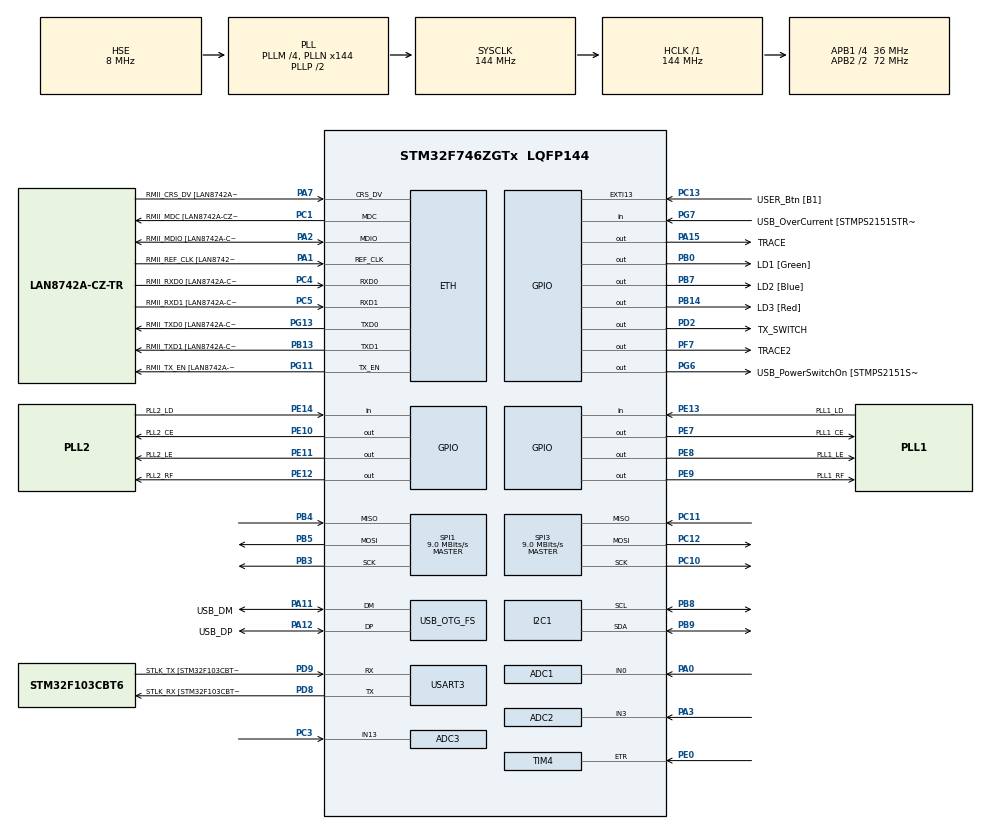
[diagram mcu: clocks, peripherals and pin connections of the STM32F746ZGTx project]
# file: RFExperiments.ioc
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ADC1.Channel-9\#ChannelRegularConversion=ADC_CHANNEL_0
ADC1.ClockPrescaler=ADC_CLOCK_SYNC_PCLK_DIV2
ADC1.ContinuousConvMode=DISABLE
ADC1.DMAAccessMode=ADC_DMAACCESSMODE_1
ADC1.DMAContinuousRequests=ENABLE
ADC1.ExternalTrigConv=ADC_EXTERNALTRIGCONV_T4_TRGO
ADC1.Mode=ADC_TRIPLEMODE_REGSIMULT
ADC1.NbrOfConversionFlag=1
ADC1.Rank-9\#ChannelRegularConversion=1
ADC1.SamplingTime-9\#ChannelRegularConversion=ADC_SAMPLETIME_3CYCLES
ADC1.master=1
ADC2.Channel-0\#ChannelRegularConversion=ADC_CHANNEL_3
ADC2.ContinuousConvMode=DISABLE
ADC2.DMAAccessMode=ADC_DMAACCESSMODE_1
ADC2.DMAContinuousRequests=DISABLE
ADC2.Mode=ADC_TRIPLEMODE_REGSIMULT
ADC2.NbrOfConversionFlag=1
ADC2.Rank-0\#ChannelRegularConversion=1
ADC2.SamplingTime-0\#ChannelRegularConversion=ADC_SAMPLETIME_3CYCLES
ADC3.Channel-10\#ChannelRegularConversion=ADC_CHANNEL_13
ADC3.ContinuousConvMode=DISABLE
ADC3.DMAAccessMode=ADC_DMAACCESSMODE_1
ADC3.DMAContinuousRequests=DISABLE
ADC3.Mode=ADC_TRIPLEMODE_REGSIMULT
ADC3.NbrOfConversionFlag=1
ADC3.Rank-10\#ChannelRegularConversion=1
ADC3.SamplingTime-10\#ChannelRegularConversion=ADC_SAMPLETIME_3CYCLES
CORTEX_M7.ART_ACCLERATOR_ENABLE=1
CORTEX_M7.CPU_DCache=Enabled
CORTEX_M7.CPU_ICache=Enabled
CORTEX_M7.PREFETCH_ENABLE=1
Dma.ADC1.0.Direction=DMA_PERIPH_TO_MEMORY
Dma.ADC1.0.FIFOMode=DMA_FIFOMODE_DISABLE
Dma.ADC1.0.Instance=DMA2_Stream0
Dma.ADC1.0.MemDataAlignment=DMA_MDATAALIGN_HALFWORD
Dma.ADC1.0.MemInc=DMA_MINC_ENABLE
Dma.ADC1.0.Mode=DMA_CIRCULAR
Dma.ADC1.0.PeriphDataAlignment=DMA_PDATAALIGN_HALFWORD
Dma.ADC1.0.PeriphInc=DMA_PINC_DISABLE
Dma.ADC1.0.Priority=DMA_PRIORITY_HIGH
Dma.Request0=ADC1
ETH.MediaInterface=ETH_MEDIA_INTERFACE_RMII
ETH.PHY_Name=LAN8742A_PHY_ADDRESS
ETH.PHY_Value=0
ETH.PhyAddress=0
I2C1.Timing=0x00808CD2
Mcu.Family=STM32F7
Mcu.Name=STM32F746ZGTx
Mcu.Package=LQFP144
NVIC.DMA2_Stream0_IRQn=true\:1\:0\:true\:false\:true\:false\:true
NVIC.OTG_FS_IRQn=true\:0\:0\:false\:false\:true\:false\:true
NVIC.PriorityGroup=NVIC_PRIORITYGROUP_4
PA0/WKUP.Signal=ADCx_IN0
PA1.GPIO_Label=RMII_REF_CLK [LAN8742A-CZ-TR_REFCLK0]
PA1.Mode=RMII
PA1.Signal=ETH_REF_CLK
PA10.GPIO_Label=USB_ID
PA10.Signal=USB_OTG_FS_ID
PA11.GPIO_Label=USB_DM
PA11.Mode=Device_Only
PA11.Signal=USB_OTG_FS_DM
PA12.GPIO_Label=USB_DP
PA12.Mode=Device_Only
PA12.Signal=USB_OTG_FS_DP
PA13.GPIO_Label=TMS
PA13.Mode=Serial_Wire
PA13.Signal=SYS_JTMS-SWDIO
PA14.GPIO_Label=TCK
PA14.Mode=Serial_Wire
PA14.Signal=SYS_JTCK-SWCLK
PA15.GPIO_Label=TRACE
PA15.GPIO_Speed=GPIO_SPEED_FREQ_VERY_HIGH
PA15.Signal=GPIO_Output
PA2.GPIO_Label=RMII_MDIO [LAN8742A-CZ-TR_MDIO]
PA2.Mode=RMII
PA2.Signal=ETH_MDIO
PA3.Signal=ADCx_IN3
PA7.GPIO_Label=RMII_CRS_DV [LAN8742A-CZ-TR_CRS_DV]
PA7.Mode=RMII
PA7.Signal=ETH_CRS_DV
PA8.GPIO_Label=USB_SOF [TP1]
PA8.Signal=USB_OTG_FS_SOF
PA9.GPIO_Label=USB_VBUS
PA9.Signal=USB_OTG_FS_VBUS
PB0.GPIO_Label=LD1 [Green]
PB0.Signal=GPIO_Output
PB13.GPIO_Label=RMII_TXD1 [LAN8742A-CZ-TR_TXD1]
PB13.Mode=RMII
PB13.Signal=ETH_TXD1
PB14.GPIO_Label=LD3 [Red]
PB14.Signal=GPIO_Output
PB3.Mode=Full_Duplex_Master
PB3.Signal=SPI1_SCK
PB4.Mode=Full_Duplex_Master
PB4.Signal=SPI1_MISO
PB5.Mode=Full_Duplex_Master
PB5.Signal=SPI1_MOSI
PB7.GPIO_Label=LD2 [Blue]
PB7.Signal=GPIO_Output
PB8.Mode=I2C
PB8.Signal=I2C1_SCL
PB9.Mode=I2C
PB9.Signal=I2C1_SDA
PC1.GPIO_Label=RMII_MDC [LAN8742A-CZ-TR_MDC]
PC1.Mode=RMII
PC1.Signal=ETH_MDC
PC10.Mode=Full_Duplex_Master
PC10.Signal=SPI3_SCK
PC11.Mode=Full_Duplex_Master
PC11.Signal=SPI3_MISO
PC12.Mode=Full_Duplex_Master
PC12.Signal=SPI3_MOSI
PC13.GPIO_Label=USER_Btn [B1]
PC13.Signal=GPXTI13
PC14/OSC32_IN.Mode=LSE-External-Oscillator
PC14/OSC32_IN.Signal=RCC_OSC32_IN
PC15/OSC32_OUT.Mode=LSE-External-Oscillator
PC15/OSC32_OUT.Signal=RCC_OSC32_OUT
PC3.Signal=ADCx_IN13
PC4.GPIO_Label=RMII_RXD0 [LAN8742A-CZ-TR_RXD0]
PC4.Mode=RMII
PC4.Signal=ETH_RXD0
PC5.GPIO_Label=RMII_RXD1 [LAN8742A-CZ-TR_RXD1]
PC5.Mode=RMII
PC5.Signal=ETH_RXD1
PD2.GPIO_Label=TX_SWITCH
PD2.GPIO_Speed=GPIO_SPEED_FREQ_VERY_HIGH
PD2.Signal=GPIO_Output
PD8.GPIO_Label=STLK_RX [STM32F103CBT6_PA3]
PD8.Mode=Asynchronous
PD8.Signal=USART3_TX
PD9.GPIO_Label=STLK_TX [STM32F103CBT6_PA2]
PD9.Mode=Asynchronous
PD9.Signal=USART3_RX
PE0.GPIO_PuPd=GPIO_PULLDOWN
PE0.Signal=S_TIM4_ETR
PE10.GPIO_Label=PLL2_CE
PE10.GPIO_Speed=GPIO_SPEED_FREQ_VERY_HIGH
PE10.Signal=GPIO_Output
PE11.GPIO_Label=PLL2_LE
PE11.GPIO_Speed=GPIO_SPEED_FREQ_VERY_HIGH
PE11.Signal=GPIO_Output
PE12.GPIO_Label=PLL2_RF
PE12.GPIO_Speed=GPIO_SPEED_FREQ_VERY_HIGH
PE12.Signal=GPIO_Output
PE13.GPIO_Label=PLL1_LD
PE13.Signal=GPIO_Input
PE14.GPIO_Label=PLL2_LD
PE14.Signal=GPIO_Input
PE7.GPIO_Label=PLL1_CE
PE7.GPIO_Speed=GPIO_SPEED_FREQ_VERY_HIGH
PE7.Signal=GPIO_Output
PE8.GPIO_Label=PLL1_LE
PE8.GPIO_Speed=GPIO_SPEED_FREQ_VERY_HIGH
PE8.Signal=GPIO_Output
PE9.GPIO_Label=PLL1_RF
PE9.GPIO_Speed=GPIO_SPEED_FREQ_VERY_HIGH
PE9.Signal=GPIO_Output
PF7.GPIO_Label=TRACE2
PF7.GPIO_Speed=GPIO_SPEED_FREQ_VERY_HIGH
PF7.Signal=GPIO_Output
PG11.GPIO_Label=RMII_TX_EN [LAN8742A-CZ-TR_TXEN]
PG11.Mode=RMII
PG11.Signal=ETH_TX_EN
PG13.GPIO_Label=RMII_TXD0 [LAN8742A-CZ-TR_TXD0]
PG13.Mode=RMII
PG13.Signal=ETH_TXD0
PG6.GPIO_Label=USB_PowerSwitchOn [STMPS2151STR_EN]
PG6.Signal=GPIO_Output
PG7.GPIO_Label=USB_OverCurrent [STMPS2151STR_FAULT]
PG7.Signal=GPIO_Input
PH0/OSC_IN.GPIO_Label=MCO [STM32F103CBT6_PA8]
PH0/OSC_IN.Mode=HSE-External-Clock-Source
PH0/OSC_IN.Signal=RCC_OSC_IN
PH1/OSC_OUT.Mode=HSE-External-Clock-Source
PH1/OSC_OUT.Signal=RCC_OSC_OUT
ProjectManager.HeapSize=0x200
ProjectManager.StackSize=0x400
ProjectManager.TargetToolchain=SW4STM32
RCC.48MHZClocksFreq_Value=24000000
RCC.AHBFreq_Value=144000000
RCC.APB1CLKDivider=RCC_HCLK_DIV4
RCC.APB1Freq_Value=36000000
RCC.APB1TimFreq_Value=72000000
RCC.APB2CLKDivider=RCC_HCLK_DIV2
RCC.APB2Freq_Value=72000000
RCC.APB2TimFreq_Value=144000000
RCC.CortexFreq_Value=144000000
RCC.HCLKFreq_Value=144000000
RCC.HSE_VALUE=8000000
RCC.HSI_VALUE=16000000
RCC.PLLM=4
RCC.PLLMUL=RCC_PLL_MUL9
RCC.PLLN=144
RCC.PLLQ=6
RCC.PRESCALERUSB=RCC_USBCLKSOURCE_PLL_DIV1_5
RCC.SYSCLKFreq_VALUE=144000000
RCC.SYSCLKSource=RCC_SYSCLKSOURCE_PLLCLK
RCC.SYSCLKSourceVirtual=RCC_SYSCLKSOURCE_PLLCLK
RCC.USBFreq_Value=48000000
RCC.VCOOutputFreq_Value=288000000
SH.ADCx_IN0.0=ADC1_IN0,IN0
SH.ADCx_IN13.0=ADC3_IN13,IN13
SH.ADCx_IN3.0=ADC2_IN3,IN3
SH.S_TIM4_ETR.0=TIM4_ETR,ClockSourceETR_Mode2
SPI1.BaudRatePrescaler=SPI_BAUDRATEPRESCALER_8
SPI1.CalculateBaudRate=9.0 MBits/s
SPI1.DataSize=SPI_DATASIZE_8BIT
SPI1.Direction=SPI_DIRECTION_2LINES
SPI1.Mode=SPI_MODE_MASTER
SPI1.VirtualType=VM_MASTER
SPI3.BaudRatePrescaler=SPI_BAUDRATEPRESCALER_4
SPI3.CalculateBaudRate=9.0 MBits/s
SPI3.DataSize=SPI_DATASIZE_8BIT
SPI3.Direction=SPI_DIRECTION_2LINES
SPI3.Mode=SPI_MODE_MASTER
SPI3.VirtualType=VM_MASTER
TIM1.Period=65535
TIM1.Prescaler=215
TIM4.Channel-Output\ Compare1\ No\ Output=TIM_CHANNEL_1
TIM4.Period=6
TIM4.TIM_MasterOutputTrigger=TIM_TRGO_OC1
TIM4.TIM_MasterSlaveMode=TIM_MASTERSLAVEMODE_ENABLE
USART3.VirtualMode-Asynchronous=VM_ASYNC
USB_DEVICE.CLASS_NAME_FS=CDC
USB_DEVICE.PRODUCT_STRING_CDC_FS=VNA
USB_DEVICE.VirtualMode-CDC_FS=Cdc
USB_DEVICE.VirtualModeFS=Cdc_FS
USB_OTG_FS.VirtualMode=Device_Only
VP_TIM1_VS_ClockSourceINT.Mode=Internal
VP_TIM4_VS_no_output1.Mode=Output Compare1 No Output
VP_USB_DEVICE_VS_USB_DEVICE_CDC_FS.Mode=CDC_FS
board=NUCLEO-F746ZG

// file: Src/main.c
/* USER CODE BEGIN Header */
/**
  ******************************************************************************
  * @file           : main.c
  * @brief          : Main program body
  ******************************************************************************
  * @attention
  *
  * <h2><center>&copy; Copyright (c) 2020 STMicroelectronics.
  * All rights reserved.</center></h2>
  *
  * This software component is licensed by ST under BSD 3-Clause license,
  * the "License"; You may not use this file except in compliance with the
  * License. You may obtain a copy of the License at:
  *                        opensource.org/licenses/BSD-3-Clause
  *
  ******************************************************************************
  */
/* USER CODE END Header */

#include "main.h"
#include "usb_device.h"

/* USER CODE BEGIN Includes */
#include "App.h"
/* USER CODE END Includes */

ADC_HandleTypeDef hadc1;
ADC_HandleTypeDef hadc2;
ADC_HandleTypeDef hadc3;
DMA_HandleTypeDef hdma_adc1;

ETH_HandleTypeDef heth;

I2C_HandleTypeDef hi2c1;

SPI_HandleTypeDef hspi1;
SPI_HandleTypeDef hspi3;

TIM_HandleTypeDef htim1;
TIM_HandleTypeDef htim4;

UART_HandleTypeDef huart3;

void SystemClock_Config(void);
static void MX_GPIO_Init(void);
static void MX_DMA_Init(void);
static void MX_ETH_Init(void);
static void MX_USART3_UART_Init(void);
static void MX_SPI1_Init(void);
static void MX_ADC1_Init(void);
static void MX_ADC2_Init(void);
static void MX_ADC3_Init(void);
static void MX_TIM1_Init(void);
static void MX_TIM4_Init(void);
static void MX_I2C1_Init(void);
static void MX_SPI3_Init(void);

int main(void)
{

  /* Enable I-Cache---------------------------------------------------------*/
  SCB_EnableICache();

  /* Enable D-Cache---------------------------------------------------------*/
  SCB_EnableDCache();

  /* MCU Configuration--------------------------------------------------------*/

  /* Reset of all peripherals, Initializes the Flash interface and the Systick. */
  HAL_Init();

  /* Configure the system clock */
  SystemClock_Config();

  /* Initialize all configured peripherals */
  MX_GPIO_Init();
  MX_DMA_Init();
  MX_USART3_UART_Init();
  MX_SPI1_Init();
  MX_ADC1_Init();
  MX_ADC2_Init();
  MX_ADC3_Init();
  MX_TIM1_Init();
  MX_TIM4_Init();
  MX_I2C1_Init();
  MX_USB_DEVICE_Init();
  MX_SPI3_Init();

  /* Infinite loop */
  /* USER CODE BEGIN WHILE */
  /*
   * Errata 2.2.1: ADC misses trigger from timer in certain conditions.
   * Work-around: Enable Clk to DAC (see Errata Sheet)
   */
  __HAL_RCC_DAC_CLK_ENABLE();
  App_Start();
  while (1)
  {
    /* USER CODE END WHILE */

  }
}

void SystemClock_Config(void)
{
  RCC_OscInitTypeDef RCC_OscInitStruct = {0};
  RCC_ClkInitTypeDef RCC_ClkInitStruct = {0};
  RCC_PeriphCLKInitTypeDef PeriphClkInitStruct = {0};

  /** Configure LSE Drive Capability
  */
  HAL_PWR_EnableBkUpAccess();
  /** Configure the main internal regulator output voltage
  */
  __HAL_RCC_PWR_CLK_ENABLE();
  __HAL_PWR_VOLTAGESCALING_CONFIG(PWR_REGULATOR_VOLTAGE_SCALE3);
  /** Initializes the CPU, AHB and APB busses clocks
  */
  RCC_OscInitStruct.OscillatorType = RCC_OSCILLATORTYPE_HSE;
  RCC_OscInitStruct.HSEState = RCC_HSE_BYPASS;
  RCC_OscInitStruct.PLL.PLLState = RCC_PLL_ON;
  RCC_OscInitStruct.PLL.PLLSource = RCC_PLLSOURCE_HSE;
  RCC_OscInitStruct.PLL.PLLM = 4;
  RCC_OscInitStruct.PLL.PLLN = 144;
  RCC_OscInitStruct.PLL.PLLP = RCC_PLLP_DIV2;
  RCC_OscInitStruct.PLL.PLLQ = 6;
  if (HAL_RCC_OscConfig(&RCC_OscInitStruct) != HAL_OK)
  {
    Error_Handler();
  }
  /** Initializes the CPU, AHB and APB busses clocks
  */
  RCC_ClkInitStruct.ClockType = RCC_CLOCKTYPE_HCLK|RCC_CLOCKTYPE_SYSCLK
                              |RCC_CLOCKTYPE_PCLK1|RCC_CLOCKTYPE_PCLK2;
  RCC_ClkInitStruct.SYSCLKSource = RCC_SYSCLKSOURCE_PLLCLK;
  RCC_ClkInitStruct.AHBCLKDivider = RCC_SYSCLK_DIV1;
  RCC_ClkInitStruct.APB1CLKDivider = RCC_HCLK_DIV4;
  RCC_ClkInitStruct.APB2CLKDivider = RCC_HCLK_DIV2;

  if (HAL_RCC_ClockConfig(&RCC_ClkInitStruct, FLASH_LATENCY_4) != HAL_OK)
  {
    Error_Handler();
  }
  PeriphClkInitStruct.PeriphClockSelection = RCC_PERIPHCLK_USART3|RCC_PERIPHCLK_I2C1
                              |RCC_PERIPHCLK_CLK48;
  PeriphClkInitStruct.Usart3ClockSelection = RCC_USART3CLKSOURCE_PCLK1;
  PeriphClkInitStruct.I2c1ClockSelection = RCC_I2C1CLKSOURCE_PCLK1;
  PeriphClkInitStruct.Clk48ClockSelection = RCC_CLK48SOURCE_PLL;
  if (HAL_RCCEx_PeriphCLKConfig(&PeriphClkInitStruct) != HAL_OK)
  {
    Error_Handler();
  }
}

static void MX_ADC1_Init(void)
{

  ADC_MultiModeTypeDef multimode = {0};
  ADC_ChannelConfTypeDef sConfig = {0};

  /** Configure the global features of the ADC (Clock, Resolution, Data Alignment and number of conversion)
  */
  hadc1.Instance = ADC1;
  hadc1.Init.ClockPrescaler = ADC_CLOCK_SYNC_PCLK_DIV2;
  hadc1.Init.Resolution = ADC_RESOLUTION_12B;
  hadc1.Init.ScanConvMode = DISABLE;
  hadc1.Init.ContinuousConvMode = DISABLE;
  hadc1.Init.DiscontinuousConvMode = DISABLE;
  hadc1.Init.ExternalTrigConvEdge = ADC_EXTERNALTRIGCONVEDGE_RISING;
  hadc1.Init.ExternalTrigConv = ADC_EXTERNALTRIGCONV_T4_TRGO;
  hadc1.Init.DataAlign = ADC_DATAALIGN_RIGHT;
  hadc1.Init.NbrOfConversion = 1;
  hadc1.Init.DMAContinuousRequests = ENABLE;
  hadc1.Init.EOCSelection = ADC_EOC_SINGLE_CONV;
  if (HAL_ADC_Init(&hadc1) != HAL_OK)
  {
    Error_Handler();
  }
  /** Configure the ADC multi-mode
  */
  multimode.Mode = ADC_TRIPLEMODE_REGSIMULT;
  multimode.DMAAccessMode = ADC_DMAACCESSMODE_1;
  multimode.TwoSamplingDelay = ADC_TWOSAMPLINGDELAY_5CYCLES;
  if (HAL_ADCEx_MultiModeConfigChannel(&hadc1, &multimode) != HAL_OK)
  {
    Error_Handler();
  }
  /** Configure for the selected ADC regular channel its corresponding rank in the sequencer and its sample time.
  */
  sConfig.Channel = ADC_CHANNEL_0;
  sConfig.Rank = ADC_REGULAR_RANK_1;
  sConfig.SamplingTime = ADC_SAMPLETIME_3CYCLES;
  if (HAL_ADC_ConfigChannel(&hadc1, &sConfig) != HAL_OK)
  {
    Error_Handler();
  }

}

static void MX_ADC2_Init(void)
{

  ADC_ChannelConfTypeDef sConfig = {0};

  /** Configure the global features of the ADC (Clock, Resolution, Data Alignment and number of conversion)
  */
  hadc2.Instance = ADC2;
  hadc2.Init.ClockPrescaler = ADC_CLOCK_SYNC_PCLK_DIV2;
  hadc2.Init.Resolution = ADC_RESOLUTION_12B;
  hadc2.Init.ScanConvMode = DISABLE;
  hadc2.Init.ContinuousConvMode = DISABLE;
  hadc2.Init.DiscontinuousConvMode = DISABLE;
  hadc2.Init.DataAlign = ADC_DATAALIGN_RIGHT;
  hadc2.Init.NbrOfConversion = 1;
  hadc2.Init.DMAContinuousRequests = DISABLE;
  hadc2.Init.EOCSelection = ADC_EOC_SINGLE_CONV;
  if (HAL_ADC_Init(&hadc2) != HAL_OK)
  {
    Error_Handler();
  }
  /** Configure for the selected ADC regular channel its corresponding rank in the sequencer and its sample time.
  */
  sConfig.Channel = ADC_CHANNEL_3;
  sConfig.Rank = ADC_REGULAR_RANK_1;
  sConfig.SamplingTime = ADC_SAMPLETIME_3CYCLES;
  if (HAL_ADC_ConfigChannel(&hadc2, &sConfig) != HAL_OK)
  {
    Error_Handler();
  }

}

static void MX_ADC3_Init(void)
{

  ADC_ChannelConfTypeDef sConfig = {0};

  /** Configure the global features of the ADC (Clock, Resolution, Data Alignment and number of conversion)
  */
  hadc3.Instance = ADC3;
  hadc3.Init.ClockPrescaler = ADC_CLOCK_SYNC_PCLK_DIV2;
  hadc3.Init.Resolution = ADC_RESOLUTION_12B;
  hadc3.Init.ScanConvMode = DISABLE;
  hadc3.Init.ContinuousConvMode = DISABLE;
  hadc3.Init.DiscontinuousConvMode = DISABLE;
  hadc3.Init.DataAlign = ADC_DATAALIGN_RIGHT;
  hadc3.Init.NbrOfConversion = 1;
  hadc3.Init.DMAContinuousRequests = DISABLE;
  hadc3.Init.EOCSelection = ADC_EOC_SINGLE_CONV;
  if (HAL_ADC_Init(&hadc3) != HAL_OK)
  {
    Error_Handler();
  }
  /** Configure for the selected ADC regular channel its corresponding rank in the sequencer and its sample time.
  */
  sConfig.Channel = ADC_CHANNEL_13;
  sConfig.Rank = ADC_REGULAR_RANK_1;
  sConfig.SamplingTime = ADC_SAMPLETIME_3CYCLES;
  if (HAL_ADC_ConfigChannel(&hadc3, &sConfig) != HAL_OK)
  {
    Error_Handler();
  }

}

static void MX_ETH_Init(void)
{

   uint8_t MACAddr[6] ;

  heth.Instance = ETH;
  heth.Init.AutoNegotiation = ETH_AUTONEGOTIATION_ENABLE;
  heth.Init.PhyAddress = LAN8742A_PHY_ADDRESS;
  MACAddr[0] = 0x00;
  MACAddr[1] = 0x80;
  MACAddr[2] = 0xE1;
  MACAddr[3] = 0x00;
  MACAddr[4] = 0x00;
  MACAddr[5] = 0x00;
  heth.Init.MACAddr = &MACAddr[0];
  heth.Init.RxMode = ETH_RXPOLLING_MODE;
  heth.Init.ChecksumMode = ETH_CHECKSUM_BY_HARDWARE;
  heth.Init.MediaInterface = ETH_MEDIA_INTERFACE_RMII;

  if (HAL_ETH_Init(&heth) != HAL_OK)
  {
    Error_Handler();
  }

}

static void MX_I2C1_Init(void)
{

  hi2c1.Instance = I2C1;
  hi2c1.Init.Timing = 0x00808CD2;
  hi2c1.Init.OwnAddress1 = 0;
  hi2c1.Init.AddressingMode = I2C_ADDRESSINGMODE_7BIT;
  hi2c1.Init.DualAddressMode = I2C_DUALADDRESS_DISABLE;
  hi2c1.Init.OwnAddress2 = 0;
  hi2c1.Init.OwnAddress2Masks = I2C_OA2_NOMASK;
  hi2c1.Init.GeneralCallMode = I2C_GENERALCALL_DISABLE;
  hi2c1.Init.NoStretchMode = I2C_NOSTRETCH_DISABLE;
  if (HAL_I2C_Init(&hi2c1) != HAL_OK)
  {
    Error_Handler();
  }
  /** Configure Analogue filter
  */
  if (HAL_I2CEx_ConfigAnalogFilter(&hi2c1, I2C_ANALOGFILTER_ENABLE) != HAL_OK)
  {
    Error_Handler();
  }
  /** Configure Digital filter
  */
  if (HAL_I2CEx_ConfigDigitalFilter(&hi2c1, 0) != HAL_OK)
  {
    Error_Handler();
  }

}

static void MX_SPI1_Init(void)
{

  /* SPI1 parameter configuration*/
  hspi1.Instance = SPI1;
  hspi1.Init.Mode = SPI_MODE_MASTER;
  hspi1.Init.Direction = SPI_DIRECTION_2LINES;
  hspi1.Init.DataSize = SPI_DATASIZE_8BIT;
  hspi1.Init.CLKPolarity = SPI_POLARITY_LOW;
  hspi1.Init.CLKPhase = SPI_PHASE_1EDGE;
  hspi1.Init.NSS = SPI_NSS_SOFT;
  hspi1.Init.BaudRatePrescaler = SPI_BAUDRATEPRESCALER_8;
  hspi1.Init.FirstBit = SPI_FIRSTBIT_MSB;
  hspi1.Init.TIMode = SPI_TIMODE_DISABLE;
  hspi1.Init.CRCCalculation = SPI_CRCCALCULATION_DISABLE;
  hspi1.Init.CRCPolynomial = 7;
  hspi1.Init.CRCLength = SPI_CRC_LENGTH_DATASIZE;
  hspi1.Init.NSSPMode = SPI_NSS_PULSE_ENABLE;
  if (HAL_SPI_Init(&hspi1) != HAL_OK)
  {
    Error_Handler();
  }

}

static void MX_SPI3_Init(void)
{

  /* SPI3 parameter configuration*/
  hspi3.Instance = SPI3;
  hspi3.Init.Mode = SPI_MODE_MASTER;
  hspi3.Init.Direction = SPI_DIRECTION_2LINES;
  hspi3.Init.DataSize = SPI_DATASIZE_8BIT;
  hspi3.Init.CLKPolarity = SPI_POLARITY_LOW;
  hspi3.Init.CLKPhase = SPI_PHASE_1EDGE;
  hspi3.Init.NSS = SPI_NSS_SOFT;
  hspi3.Init.BaudRatePrescaler = SPI_BAUDRATEPRESCALER_4;
  hspi3.Init.FirstBit = SPI_FIRSTBIT_MSB;
  hspi3.Init.TIMode = SPI_TIMODE_DISABLE;
  hspi3.Init.CRCCalculation = SPI_CRCCALCULATION_DISABLE;
  hspi3.Init.CRCPolynomial = 7;
  hspi3.Init.CRCLength = SPI_CRC_LENGTH_DATASIZE;
  hspi3.Init.NSSPMode = SPI_NSS_PULSE_ENABLE;
  if (HAL_SPI_Init(&hspi3) != HAL_OK)
  {
    Error_Handler();
  }

}

static void MX_TIM1_Init(void)
{

  TIM_ClockConfigTypeDef sClockSourceConfig = {0};
  TIM_MasterConfigTypeDef sMasterConfig = {0};

  htim1.Instance = TIM1;
  htim1.Init.Prescaler = 215;
  htim1.Init.CounterMode = TIM_COUNTERMODE_UP;
  htim1.Init.Period = 65535;
  htim1.Init.ClockDivision = TIM_CLOCKDIVISION_DIV1;
  htim1.Init.RepetitionCounter = 0;
  htim1.Init.AutoReloadPreload = TIM_AUTORELOAD_PRELOAD_DISABLE;
  if (HAL_TIM_Base_Init(&htim1) != HAL_OK)
  {
    Error_Handler();
  }
  sClockSourceConfig.ClockSource = TIM_CLOCKSOURCE_INTERNAL;
  if (HAL_TIM_ConfigClockSource(&htim1, &sClockSourceConfig) != HAL_OK)
  {
    Error_Handler();
  }
  sMasterConfig.MasterOutputTrigger = TIM_TRGO_RESET;
  sMasterConfig.MasterOutputTrigger2 = TIM_TRGO2_RESET;
  sMasterConfig.MasterSlaveMode = TIM_MASTERSLAVEMODE_DISABLE;
  if (HAL_TIMEx_MasterConfigSynchronization(&htim1, &sMasterConfig) != HAL_OK)
  {
    Error_Handler();
  }

}

static void MX_TIM4_Init(void)
{

  TIM_ClockConfigTypeDef sClockSourceConfig = {0};
  TIM_MasterConfigTypeDef sMasterConfig = {0};
  TIM_OC_InitTypeDef sConfigOC = {0};

  htim4.Instance = TIM4;
  htim4.Init.Prescaler = 0;
  htim4.Init.CounterMode = TIM_COUNTERMODE_UP;
  htim4.Init.Period = 6;
  htim4.Init.ClockDivision = TIM_CLOCKDIVISION_DIV1;
  htim4.Init.AutoReloadPreload = TIM_AUTORELOAD_PRELOAD_DISABLE;
  if (HAL_TIM_Base_Init(&htim4) != HAL_OK)
  {
    Error_Handler();
  }
  sClockSourceConfig.ClockSource = TIM_CLOCKSOURCE_ETRMODE2;
  sClockSourceConfig.ClockPolarity = TIM_CLOCKPOLARITY_NONINVERTED;
  sClockSourceConfig.ClockPrescaler = TIM_CLOCKPRESCALER_DIV1;
  sClockSourceConfig.ClockFilter = 0;
  if (HAL_TIM_ConfigClockSource(&htim4, &sClockSourceConfig) != HAL_OK)
  {
    Error_Handler();
  }
  if (HAL_TIM_OC_Init(&htim4) != HAL_OK)
  {
    Error_Handler();
  }
  sMasterConfig.MasterOutputTrigger = TIM_TRGO_OC1;
  sMasterConfig.MasterSlaveMode = TIM_MASTERSLAVEMODE_ENABLE;
  if (HAL_TIMEx_MasterConfigSynchronization(&htim4, &sMasterConfig) != HAL_OK)
  {
    Error_Handler();
  }
  sConfigOC.OCMode = TIM_OCMODE_TIMING;
  sConfigOC.Pulse = 0;
  sConfigOC.OCPolarity = TIM_OCPOLARITY_HIGH;
  sConfigOC.OCFastMode = TIM_OCFAST_DISABLE;
  if (HAL_TIM_OC_ConfigChannel(&htim4, &sConfigOC, TIM_CHANNEL_1) != HAL_OK)
  {
    Error_Handler();
  }

}

static void MX_USART3_UART_Init(void)
{

  huart3.Instance = USART3;
  huart3.Init.BaudRate = 115200;
  huart3.Init.WordLength = UART_WORDLENGTH_8B;
  huart3.Init.StopBits = UART_STOPBITS_1;
  huart3.Init.Parity = UART_PARITY_NONE;
  huart3.Init.Mode = UART_MODE_TX_RX;
  huart3.Init.HwFlowCtl = UART_HWCONTROL_NONE;
  huart3.Init.OverSampling = UART_OVERSAMPLING_16;
  huart3.Init.OneBitSampling = UART_ONE_BIT_SAMPLE_DISABLE;
  huart3.AdvancedInit.AdvFeatureInit = UART_ADVFEATURE_NO_INIT;
  if (HAL_UART_Init(&huart3) != HAL_OK)
  {
    Error_Handler();
  }

}

static void MX_DMA_Init(void)
{
  /* DMA controller clock enable */
  __HAL_RCC_DMA2_CLK_ENABLE();

  /* DMA interrupt init */
  /* DMA2_Stream0_IRQn interrupt configuration */
  HAL_NVIC_SetPriority(DMA2_Stream0_IRQn, 1, 0);
  HAL_NVIC_EnableIRQ(DMA2_Stream0_IRQn);

}

static void MX_GPIO_Init(void)
{
  GPIO_InitTypeDef GPIO_InitStruct = {0};

  /* GPIO Ports Clock Enable */
  __HAL_RCC_GPIOC_CLK_ENABLE();
  __HAL_RCC_GPIOF_CLK_ENABLE();
  __HAL_RCC_GPIOH_CLK_ENABLE();
  __HAL_RCC_GPIOA_CLK_ENABLE();
  __HAL_RCC_GPIOB_CLK_ENABLE();
  __HAL_RCC_GPIOE_CLK_ENABLE();
  __HAL_RCC_GPIOD_CLK_ENABLE();
  __HAL_RCC_GPIOG_CLK_ENABLE();

  /*Configure GPIO pin Output Level */
  HAL_GPIO_WritePin(TRACE2_GPIO_Port, TRACE2_Pin, GPIO_PIN_RESET);

  /*Configure GPIO pin Output Level */
  HAL_GPIO_WritePin(GPIOB, LD1_Pin|LD3_Pin|LD2_Pin, GPIO_PIN_RESET);

  /*Configure GPIO pin Output Level */
  HAL_GPIO_WritePin(GPIOE, PLL1_CE_Pin|PLL1_LE_Pin|PLL1_RF_Pin|PLL2_CE_Pin
                          |PLL2_LE_Pin|PLL2_RF_Pin, GPIO_PIN_RESET);

  /*Configure GPIO pin Output Level */
  HAL_GPIO_WritePin(USB_PowerSwitchOn_GPIO_Port, USB_PowerSwitchOn_Pin, GPIO_PIN_RESET);

  /*Configure GPIO pin Output Level */
  HAL_GPIO_WritePin(TRACE_GPIO_Port, TRACE_Pin, GPIO_PIN_RESET);

  /*Configure GPIO pin Output Level */
  HAL_GPIO_WritePin(TX_SWITCH_GPIO_Port, TX_SWITCH_Pin, GPIO_PIN_RESET);

  /*Configure GPIO pin : USER_Btn_Pin */
  GPIO_InitStruct.Pin = USER_Btn_Pin;
  GPIO_InitStruct.Mode = GPIO_MODE_IT_RISING;
  GPIO_InitStruct.Pull = GPIO_NOPULL;
  HAL_GPIO_Init(USER_Btn_GPIO_Port, &GPIO_InitStruct);

  /*Configure GPIO pin : TRACE2_Pin */
  GPIO_InitStruct.Pin = TRACE2_Pin;
  GPIO_InitStruct.Mode = GPIO_MODE_OUTPUT_PP;
  GPIO_InitStruct.Pull = GPIO_NOPULL;
  GPIO_InitStruct.Speed = GPIO_SPEED_FREQ_VERY_HIGH;
  HAL_GPIO_Init(TRACE2_GPIO_Port, &GPIO_InitStruct);

  /*Configure GPIO pins : LD1_Pin LD3_Pin LD2_Pin */
  GPIO_InitStruct.Pin = LD1_Pin|LD3_Pin|LD2_Pin;
  GPIO_InitStruct.Mode = GPIO_MODE_OUTPUT_PP;
  GPIO_InitStruct.Pull = GPIO_NOPULL;
  GPIO_InitStruct.Speed = GPIO_SPEED_FREQ_LOW;
  HAL_GPIO_Init(GPIOB, &GPIO_InitStruct);

  /*Configure GPIO pins : PLL1_CE_Pin PLL1_LE_Pin PLL1_RF_Pin PLL2_CE_Pin
                           PLL2_LE_Pin PLL2_RF_Pin */
  GPIO_InitStruct.Pin = PLL1_CE_Pin|PLL1_LE_Pin|PLL1_RF_Pin|PLL2_CE_Pin
                          |PLL2_LE_Pin|PLL2_RF_Pin;
  GPIO_InitStruct.Mode = GPIO_MODE_OUTPUT_PP;
  GPIO_InitStruct.Pull = GPIO_NOPULL;
  GPIO_InitStruct.Speed = GPIO_SPEED_FREQ_VERY_HIGH;
  HAL_GPIO_Init(GPIOE, &GPIO_InitStruct);

  /*Configure GPIO pins : PLL1_LD_Pin PLL2_LD_Pin */
  GPIO_InitStruct.Pin = PLL1_LD_Pin|PLL2_LD_Pin;
  GPIO_InitStruct.Mode = GPIO_MODE_INPUT;
  GPIO_InitStruct.Pull = GPIO_NOPULL;
  HAL_GPIO_Init(GPIOE, &GPIO_InitStruct);

  /*Configure GPIO pin : USB_PowerSwitchOn_Pin */
  GPIO_InitStruct.Pin = USB_PowerSwitchOn_Pin;
  GPIO_InitStruct.Mode = GPIO_MODE_OUTPUT_PP;
  GPIO_InitStruct.Pull = GPIO_NOPULL;
  GPIO_InitStruct.Speed = GPIO_SPEED_FREQ_LOW;
  HAL_GPIO_Init(USB_PowerSwitchOn_GPIO_Port, &GPIO_InitStruct);

  /*Configure GPIO pin : USB_OverCurrent_Pin */
  GPIO_InitStruct.Pin = USB_OverCurrent_Pin;
  GPIO_InitStruct.Mode = GPIO_MODE_INPUT;
  GPIO_InitStruct.Pull = GPIO_NOPULL;
  HAL_GPIO_Init(USB_OverCurrent_GPIO_Port, &GPIO_InitStruct);

  /*Configure GPIO pin : TRACE_Pin */
  GPIO_InitStruct.Pin = TRACE_Pin;
  GPIO_InitStruct.Mode = GPIO_MODE_OUTPUT_PP;
  GPIO_InitStruct.Pull = GPIO_NOPULL;
  GPIO_InitStruct.Speed = GPIO_SPEED_FREQ_VERY_HIGH;
  HAL_GPIO_Init(TRACE_GPIO_Port, &GPIO_InitStruct);

  /*Configure GPIO pin : TX_SWITCH_Pin */
  GPIO_InitStruct.Pin = TX_SWITCH_Pin;
  GPIO_InitStruct.Mode = GPIO_MODE_OUTPUT_PP;
  GPIO_InitStruct.Pull = GPIO_NOPULL;
  GPIO_InitStruct.Speed = GPIO_SPEED_FREQ_VERY_HIGH;
  HAL_GPIO_Init(TX_SWITCH_GPIO_Port, &GPIO_InitStruct);

}

void Error_Handler(void)
{
}

/************************ (C) COPYRIGHT STMicroelectronics *****END OF FILE****/
